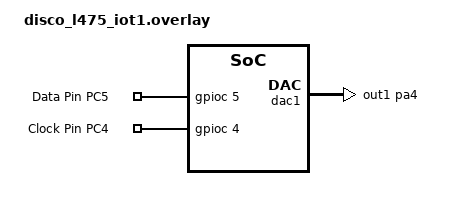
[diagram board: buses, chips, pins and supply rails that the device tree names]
/ {
    gpio_keys {
		compatible = "gpio-keys";
		data_pin: pin_c5 {
			label = "Data Pin PC5";
			gpios = <&gpioc 5 GPIO_ACTIVE_HIGH>;
		};

        clk_pin: pin_c4 {
			label = "Clock Pin PC4";
			gpios = <&gpioc 4 GPIO_ACTIVE_HIGH>;
		};
	};

    aliases {
        datapin = &data_pin;
        clkpin = &clk_pin;
    };
};

&dac1 {
	status = "okay";
	pinctrl-0 = <&dac1_out1_pa4>;
	pinctrl-names = "default";
};
